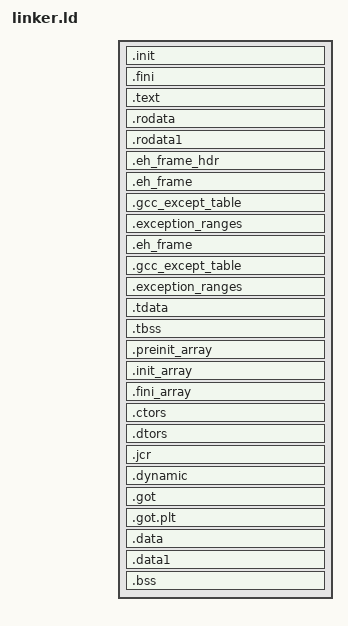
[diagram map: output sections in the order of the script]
/* Script for -z combreloc: combine and sort reloc sections */
/* Copyright (C) 2014 Free Software Foundation, Inc.
   Copying and distribution of this script, with or without modification,
   are permitted in any medium without royalty provided the copyright
   notice and this notice are preserved.  */
/* Modified for Hellbender OS. The above license applies to modifications. */
OUTPUT_FORMAT("binary")
ENTRY(_start)

_hellbender_module_info = DEFINED(_hellbender_module_info) ? _hellbender_module_info : 0;
_hellbender_module_org = DEFINED(_hellbender_module_org) ? _hellbender_module_org : 0x800000;

/* Tell where the various sections of the object files will be put in the final
   kernel image. */
SECTIONS
{
	/* Core services are based at the end of our address space. */
	. = _hellbender_module_org;
        _hellbender_module_bottom = .;
        _hellbender_text_bottom = .;

	/* The IDC table and module header must be first,
           followed by the standard .text section. */
        .init :
        {
                *(.idc_table)
                *(.module_header)
                KEEP (*(SORT_NONE(.init)))
        }
        .fini :
        {
                KEEP (*(SORT_NONE(.fini)))
        }
	.text :
	{
                *(.text.unlikely .text.*_unlikely .text.unlikely.*)
                *(.text.exit .text.exit.*)
                *(.text.startup .text.startup.*)
                *(.text.hot .text.hot.*)
                *(.text .stub .text.* .gnu.linkonce.t.*)
                . = ALIGN(4K);
                *(.bootstrap) /* bootstrap must be the sole thing in a page. */
                . = ALIGN(4K);
	}

	/* Read-only data. */
        .rodata : { *(.rodata .rodata.* .gnu.linkonce.r.*) }
        .rodata1  : { *(.rodata1) }
        .eh_frame_hdr : { *(.eh_frame_hdr) }
        .eh_frame : ONLY_IF_RO { KEEP (*(.eh_frame)) }
        .gcc_except_table : ONLY_IF_RO { *(.gcc_except_table .gcc_except_table.*) }
        /* These sections are generated by the Sun/Oracle C++ compiler.  */
        .exception_ranges   : ONLY_IF_RO { *(.exception_ranges .exception_ranges*) }

        _hellbender_text_top = .;
        . = ALIGN(4K);

	/* Read-write data (initialized) */
        /* Exception handling  */
        .eh_frame       : ONLY_IF_RW { KEEP (*(.eh_frame)) }
        .gcc_except_table   : ONLY_IF_RW { *(.gcc_except_table .gcc_except_table.*) }
        .exception_ranges   : ONLY_IF_RW { *(.exception_ranges .exception_ranges*) }
        /* Thread Local Storage sections  */
        .tdata	  : { *(.tdata .tdata.* .gnu.linkonce.td.*) }
        .tbss		  : { *(.tbss .tbss.* .gnu.linkonce.tb.*) *(.tcommon) }
        .preinit_array     :
        {
          PROVIDE_HIDDEN (__preinit_array_start = .);
          KEEP (*(.preinit_array))
          PROVIDE_HIDDEN (__preinit_array_end = .);
         }
         .init_array     :
         {
           PROVIDE_HIDDEN (__init_array_start = .);
           KEEP (*(SORT(.init_array.*)))
           KEEP (*(.init_array ))
           PROVIDE_HIDDEN (__init_array_end = .);
         }
         .fini_array     :
         {
           PROVIDE_HIDDEN (__fini_array_start = .);
           KEEP (*(SORT(.fini_array.*)))
           KEEP (*(.fini_array ))
           PROVIDE_HIDDEN (__fini_array_end = .);
         }
         .ctors          :
         {
           /* gcc uses crtbegin.o to find the start of
              the constructors, so we make sure it is
              first.  Because this is a wildcard, it
              doesn't matter if the user does not
              actually link against crtbegin.o; the
              linker won't look for a file to match a
              wildcard.  The wildcard also means that it
              doesn't matter which directory crtbegin.o
              is in.  */
           KEEP (*crtbegin.o(.ctors))
           KEEP (*crtbegin?.o(.ctors))
           /* We don't want to include the .ctor section from
              the crtend.o file until after the sorted ctors.
              The .ctor section from the crtend file contains the
              end of ctors marker and it must be last */
           KEEP (*(EXCLUDE_FILE (*crtend.o *crtend?.o ) .ctors))
           KEEP (*(SORT(.ctors.*)))
           KEEP (*(.ctors))
         }
         .dtors          :
         {
           KEEP (*crtbegin.o(.dtors))
           KEEP (*crtbegin?.o(.dtors))
           KEEP (*(EXCLUDE_FILE (*crtend.o *crtend?.o ) .dtors))
           KEEP (*(SORT(.dtors.*)))
           KEEP (*(.dtors))
         }
         .jcr            : { KEEP (*(.jcr)) }
         .dynamic        : { *(.dynamic) }
         .got            : { *(.got) *(.igot) }
         //. = DATA_SEGMENT_RELRO_END (SIZEOF (.got.plt) >= 12 ? 12 : 0, .);
         .got.plt        : { *(.got.plt)  *(.igot.plt) }
         .data           :
         {
           *(.data .data.* .gnu.linkonce.d.*)
           SORT(CONSTRUCTORS)
         }
         .data1          : { *(.data1) }

	/* Read-write data (uninitialized) and stack */
        .bss            :
        {
          *(.dynbss)
          *(.bss .bss.* .gnu.linkonce.b.*)
          *(COMMON)
          /* Align here to ensure that the .bss section occupies space up to
             _end.  Align after .bss to ensure correct alignment even if the
             .bss section disappears because there are no input sections.
             FIXME: Why do we need it? When there is no .bss section, we don't
             pad the .data section.  */
          . = ALIGN(. != 0 ? 32 / 8 : 1);
        }
        . = ALIGN(32 / 8);
        . = SEGMENT_START("ldata-segment", .);
        . = ALIGN(32 / 8);

        _hellbender_module_top = .; /*_end;*/

        _hellbender_checksum = 0x1337 + 0xc0de + (_hellbender_module_bottom>>16) + (_hellbender_module_bottom&0xffff) + (_hellbender_module_top>>16) + (_hellbender_module_top&0xffff) + (_hellbender_text_bottom>>16) + (_hellbender_text_bottom&0xffff) + (_hellbender_text_top>>16) + (_hellbender_text_top&0xffff) + (_start>>16) + (_start&0xffff) + (_hellbender_module_info&0xffff) + (_hellbender_module_info>>16);
}
